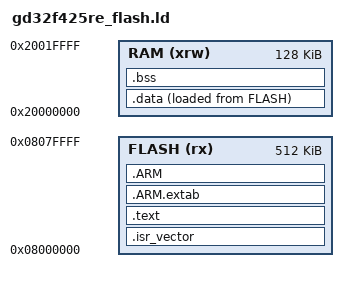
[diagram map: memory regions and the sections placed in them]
/* gd32f425re_flash.ld */
/* Linker script for GD32F425RET6 grblHAL port.
   Application starts at 0x0800_0000 (no bootloader). */

ENTRY(Reset_Handler)

MEMORY
{
  RAM (xrw)        : ORIGIN = 0x20000000, LENGTH = 128K
  FLASH (rx)       : ORIGIN = 0x08000000, LENGTH = 512K
}

_estack = ORIGIN(RAM) + LENGTH(RAM);
_Min_Heap_Size = 0x200;
_Min_Stack_Size = 0x400;

SECTIONS
{
  .isr_vector :
  {
    . = ALIGN(4);
    KEEP(*(.isr_vector))
    . = ALIGN(4);
  } > FLASH

  .text :
  {
    . = ALIGN(4);
    *(.text)
    *(.text*)
    *(.rodata)
    *(.rodata*)
    *(.glue_7)
    *(.glue_7t)
    KEEP (*(.init))
    KEEP (*(.fini))
    . = ALIGN(4);
    _etext = .;
  } > FLASH

  .ARM.extab :
  {
    *(.ARM.extab* .gnu.linkonce.armextab.*)
  } > FLASH

  .ARM :
  {
    __exidx_start = .;
    *(.ARM.exidx*)
    __exidx_end = .;
  } > FLASH

  _sidata = LOADADDR(.data);

  .data :
  {
    . = ALIGN(4);
    _sdata = .;
    *(.data)
    *(.data*)
    . = ALIGN(4);
    _edata = .;
  } > RAM AT > FLASH

  . = ALIGN(4);
  .bss :
  {
    _sbss = .;
    __bss_start__ = _sbss;
    *(.bss)
    *(.bss*)
    *(COMMON)
    . = ALIGN(4);
    _ebss = .;
    __bss_end__ = _ebss;
  } > RAM

  _end = .;
}
